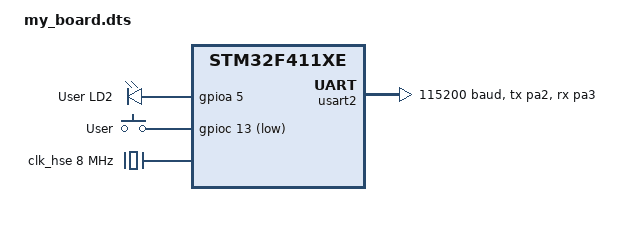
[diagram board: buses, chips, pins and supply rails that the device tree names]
/dts-v1/;

#include <st/f4/stm32f411Xe.dtsi>
#include <st/f4/stm32f411r(c-e)tx-pinctrl.dtsi>
/ {
    chosen {
        zephyr,console = &usart2;
        zephyr,shell-uart = &usart2;
        zephyr,sram = &sram0;
        zephyr,flash = &flash0;
    };

    led {
        compatible = "gpio-leds";

        ld_2: led {
            gpios = <&gpioa 5 GPIO_ACTIVE_HIGH>;
            label = "User LD2";
        };
    };

    key {
        compatible = "gpio-keys";

        b_1: button {
            label = "User";
            gpios = <&gpioc 13 GPIO_ACTIVE_LOW>;
        };
    };

    aliases {
        led0 = &ld_2;
        sw0 = &b_1;
    };
};

&clk_hse {
    hse-bypass;
    clock-frequency = <DT_FREQ_M(8)>;
    status = "okay";
};

&pll {
    div-m = <4>;
    mul-n = <200>;
    div-p = <4>;
    clocks = <&clk_hse>;
    status = "okay";
};

&rcc {
    clocks = <&pll>;
    clock-frequency = <DT_FREQ_M(100)>;
    ahb-prescaler = <1>;
    apb1-prescaler = <2>;
    apb2-prescaler = <1>;
};

&usart2 {
    pinctrl-0 = <&usart2_tx_pa2 &usart2_rx_pa3>;
    pinctrl-names = "default";
    current-speed = <115200>;
    status = "okay";
};

